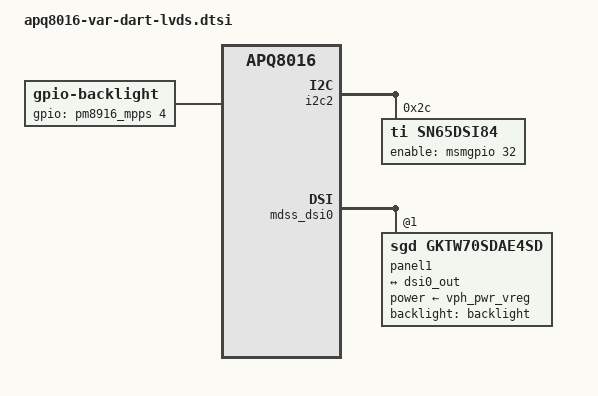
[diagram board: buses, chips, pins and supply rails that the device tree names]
/ {
	backlight: backlight {
		compatible = "gpio-backlight";
		gpios = <&pm8916_mpps 4 GPIO_ACTIVE_HIGH>;
		default-on;
	};
};

&i2c2 {
	sn65dsi84@2c {
		status = "ok";
		compatible = "ti,sn65dsi84";
		reg = <0x2c>;
		enable-gpios =<&msmgpio 32 GPIO_ACTIVE_HIGH>;
		sn65dsi84,addresses = <	0x09 0x0A 0x0B 0x0D 0x10 0x11 0x12 0x13 
					0x18 0x19 0x1A 0x1B 0x20 0x21 0x22 0x23 
					0x24 0x25 0x26 0x27 0x28 0x29 0x2A 0x2B 
					0x2C 0x2D 0x2E 0x2F 0x30 0x31 0x32 0x33 
					0x34 0x35 0x36 0x37 0x38 0x39 0x3A 0x3B 
					0x3C 0x3D 0x3E 0x0D>;
		sn65dsi84,values =    <	0x00 0x01 0x10 0x00 0x26 0x00 0x11 0x00 
					0x7a 0x00 0x03 0x00 0x20 0x03 0x00 0x00 
					0x00 0x00 0x00 0x00 0x21 0x00 0x00 0x00 
					0x30 0x00 0x00 0x00 0x03 0x00 0x00 0x00 
					0x28 0x00 0x00 0x00 0x00 0x00 0x00 0x00 
					0x00 0x00 0x00 0x01>;
	};
};

&dsi0_out {
	remote-endpoint = <&panel_in>;
	data-lanes = <0 1 2 3>;
};


&mdss_dsi0 {
        #address-cells = <1>;
        #size-cells = <0>;
 	status = "ok";
	panel1:panel@11{
		reg = <0x1>;
		status = "ok";
		compatible = "sgd,gktw70sdae4sd";
		backlight = <&backlight>;
		power-supply = <&vph_pwr_vreg>;

		pinctrl-names = "default","sleep";
		pinctrl-0 = <&adv7533_switch_active>;
		pinctrl-1 = <&adv7533_switch_suspend>;

		port {
			panel_in: endpoint {
				remote-endpoint = <&dsi0_out>;
			};
		};
	};
};

